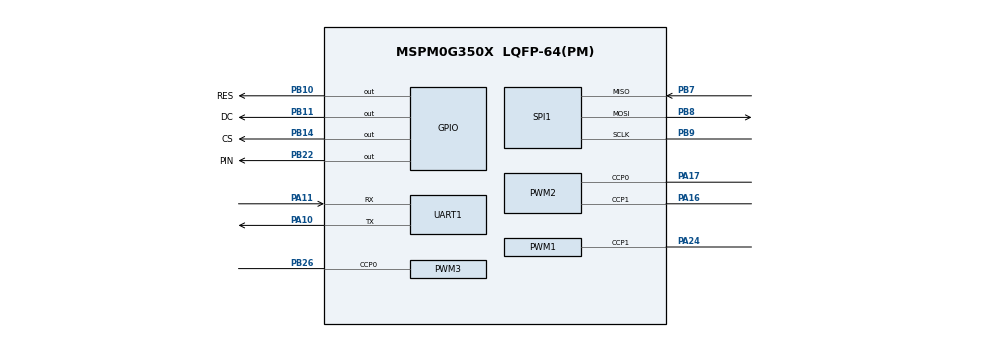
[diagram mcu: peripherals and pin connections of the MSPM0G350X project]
/**
 * @cliArgs --device "MSPM0G350X" --part "Default" --package "LQFP-64(PM)" --product "mspm0_sdk@2.04.00.06"
 * @versions {"tool":"1.22.0+3893"}
 */

/**
 * Import the modules used in this configuration.
 */
const GPIO   = scripting.addModule("/ti/driverlib/GPIO", {}, false);
const GPIO1  = GPIO.addInstance();
const GPIO2  = GPIO.addInstance();
const GPIO3  = GPIO.addInstance();
const GPIO4  = GPIO.addInstance();
const GPIO5  = GPIO.addInstance();
const GPIO6  = GPIO.addInstance();
const GPIO7  = GPIO.addInstance();
const GPIO8  = GPIO.addInstance();
const GPIO9  = GPIO.addInstance();
const PWM    = scripting.addModule("/ti/driverlib/PWM", {}, false);
const PWM1   = PWM.addInstance();
const PWM2   = PWM.addInstance();
const PWM3   = PWM.addInstance();
const SPI    = scripting.addModule("/ti/driverlib/SPI", {}, false);
const SPI1   = SPI.addInstance();
const SYSCTL = scripting.addModule("/ti/driverlib/SYSCTL");
const TIMER  = scripting.addModule("/ti/driverlib/TIMER", {}, false);
const TIMER1 = TIMER.addInstance();
const TIMER2 = TIMER.addInstance();
const UART   = scripting.addModule("/ti/driverlib/UART", {}, false);
const UART1  = UART.addInstance();
const UART2  = UART.addInstance();

/**
 * Write custom configuration values to the imported modules.
 */
const divider9       = system.clockTree["UDIV"];
divider9.divideValue = 2;

const mux4       = system.clockTree["EXHFMUX"];
mux4.inputSelect = "EXHFMUX_XTAL";

const mux8       = system.clockTree["HSCLKMUX"];
mux8.inputSelect = "HSCLKMUX_SYSPLL2X";

const mux12       = system.clockTree["SYSPLLMUX"];
mux12.inputSelect = "zSYSPLLMUX_HFCLK";

const pinFunction4        = system.clockTree["HFXT"];
pinFunction4.inputFreq    = 40;
pinFunction4.enable       = true;
pinFunction4.HFCLKMonitor = true;
pinFunction4.HFXTStartup  = 20;

GPIO1.$name                          = "LED";
GPIO1.associatedPins[0].$name        = "PIN";
GPIO1.associatedPins[0].ioStructure  = "SD";
GPIO1.associatedPins[0].assignedPort = "PORTB";
GPIO1.associatedPins[0].assignedPin  = "22";
GPIO1.associatedPins[0].pin.$assign  = "PB22";

const Board = scripting.addModule("/ti/driverlib/Board", {}, false);

GPIO2.$name                         = "OLED";
GPIO2.port                          = "PORTB";
GPIO2.associatedPins.create(3);
GPIO2.associatedPins[0].$name       = "RES";
GPIO2.associatedPins[0].ioStructure = "SD";
GPIO2.associatedPins[0].assignedPin = "10";
GPIO2.associatedPins[0].pin.$assign = "PB10";
GPIO2.associatedPins[1].$name       = "DC";
GPIO2.associatedPins[1].ioStructure = "SD";
GPIO2.associatedPins[1].assignedPin = "11";
GPIO2.associatedPins[1].pin.$assign = "PB11";
GPIO2.associatedPins[2].$name       = "CS";
GPIO2.associatedPins[2].ioStructure = "SD";
GPIO2.associatedPins[2].assignedPin = "14";
GPIO2.associatedPins[2].pin.$assign = "PB14";

GPIO3.$name                              = "KEY";
GPIO3.associatedPins.create(4);
GPIO3.associatedPins[0].$name            = "KEY1";
GPIO3.associatedPins[0].direction        = "INPUT";
GPIO3.associatedPins[0].assignedPort     = "PORTA";
GPIO3.associatedPins[0].internalResistor = "PULL_UP";
GPIO3.associatedPins[0].assignedPin      = "22";
GPIO3.associatedPins[1].$name            = "KEY2";
GPIO3.associatedPins[1].direction        = "INPUT";
GPIO3.associatedPins[1].internalResistor = "PULL_UP";
GPIO3.associatedPins[1].assignedPort     = "PORTA";
GPIO3.associatedPins[1].assignedPin      = "8";
GPIO3.associatedPins[2].$name            = "KEY3";
GPIO3.associatedPins[2].direction        = "INPUT";
GPIO3.associatedPins[2].internalResistor = "PULL_UP";
GPIO3.associatedPins[2].assignedPort     = "PORTB";
GPIO3.associatedPins[2].assignedPin      = "23";
GPIO3.associatedPins[3].$name            = "KEY4";
GPIO3.associatedPins[3].direction        = "INPUT";
GPIO3.associatedPins[3].internalResistor = "PULL_UP";
GPIO3.associatedPins[3].assignedPort     = "PORTB";
GPIO3.associatedPins[3].assignedPin      = "21";

GPIO4.$name                          = "IIC_Software";
GPIO4.port                           = "PORTA";
GPIO4.associatedPins.create(2);
GPIO4.associatedPins[0].$name        = "SCL";
GPIO4.associatedPins[0].initialValue = "SET";
GPIO4.associatedPins[0].ioStructure  = "OD";
GPIO4.associatedPins[0].assignedPin  = "1";
GPIO4.associatedPins[1].$name        = "SDA";
GPIO4.associatedPins[1].initialValue = "SET";
GPIO4.associatedPins[1].ioStructure  = "OD";
GPIO4.associatedPins[1].assignedPin  = "0";

GPIO5.$name                          = "TB6612";
GPIO5.associatedPins.create(9);
GPIO5.associatedPins[0].initialValue = "SET";
GPIO5.associatedPins[0].$name        = "AIN1";
GPIO5.associatedPins[0].assignedPort = "PORTA";
GPIO5.associatedPins[0].assignedPin  = "12";
GPIO5.associatedPins[1].$name        = "AIN2";
GPIO5.associatedPins[1].initialValue = "SET";
GPIO5.associatedPins[1].assignedPort = "PORTA";
GPIO5.associatedPins[1].assignedPin  = "13";
GPIO5.associatedPins[2].$name        = "BIN1";
GPIO5.associatedPins[2].initialValue = "SET";
GPIO5.associatedPins[2].assignedPort = "PORTA";
GPIO5.associatedPins[2].assignedPin  = "14";
GPIO5.associatedPins[3].$name        = "BIN2";
GPIO5.associatedPins[3].initialValue = "SET";
GPIO5.associatedPins[3].assignedPort = "PORTA";
GPIO5.associatedPins[3].assignedPin  = "15";
GPIO5.associatedPins[4].$name        = "CIN1";
GPIO5.associatedPins[4].initialValue = "SET";
GPIO5.associatedPins[4].assignedPort = "PORTB";
GPIO5.associatedPins[4].assignedPin  = "12";
GPIO5.associatedPins[5].$name        = "CIN2";
GPIO5.associatedPins[5].initialValue = "SET";
GPIO5.associatedPins[5].assignedPort = "PORTB";
GPIO5.associatedPins[5].assignedPin  = "13";
GPIO5.associatedPins[6].$name        = "DIN1";
GPIO5.associatedPins[6].initialValue = "SET";
GPIO5.associatedPins[6].assignedPort = "PORTB";
GPIO5.associatedPins[6].assignedPin  = "19";
GPIO5.associatedPins[7].initialValue = "SET";
GPIO5.associatedPins[7].assignedPort = "PORTB";
GPIO5.associatedPins[7].assignedPin  = "20";
GPIO5.associatedPins[7].$name        = "DIN2";
GPIO5.associatedPins[8].$name        = "STBY";
GPIO5.associatedPins[8].assignedPort = "PORTB";
GPIO5.associatedPins[8].assignedPin  = "24";

GPIO6.$name                               = "ENCODER";
GPIO6.associatedPins.create(8);
GPIO6.associatedPins[0].$name             = "E1A";
GPIO6.associatedPins[0].direction         = "INPUT";
GPIO6.associatedPins[0].assignedPort      = "PORTB";
GPIO6.associatedPins[0].assignedPin       = "18";
GPIO6.associatedPins[0].interruptEn       = true;
GPIO6.associatedPins[0].interruptPriority = "0";
GPIO6.associatedPins[0].polarity          = "RISE";
GPIO6.associatedPins[1].$name             = "E1B";
GPIO6.associatedPins[1].direction         = "INPUT";
GPIO6.associatedPins[1].assignedPort      = "PORTA";
GPIO6.associatedPins[1].assignedPin       = "25";
GPIO6.associatedPins[1].interruptEn       = true;
GPIO6.associatedPins[1].interruptPriority = "0";
GPIO6.associatedPins[1].polarity          = "RISE";
GPIO6.associatedPins[2].$name             = "E2A";
GPIO6.associatedPins[2].direction         = "INPUT";
GPIO6.associatedPins[2].assignedPort      = "PORTA";
GPIO6.associatedPins[2].assignedPin       = "26";
GPIO6.associatedPins[2].interruptEn       = true;
GPIO6.associatedPins[2].interruptPriority = "0";
GPIO6.associatedPins[2].polarity          = "RISE";
GPIO6.associatedPins[3].$name             = "E2B";
GPIO6.associatedPins[3].direction         = "INPUT";
GPIO6.associatedPins[3].assignedPort      = "PORTA";
GPIO6.associatedPins[3].assignedPin       = "27";
GPIO6.associatedPins[3].interruptEn       = true;
GPIO6.associatedPins[3].interruptPriority = "0";
GPIO6.associatedPins[3].polarity          = "RISE";
GPIO6.associatedPins[4].$name             = "E3A";
GPIO6.associatedPins[4].direction         = "INPUT";
GPIO6.associatedPins[4].assignedPort      = "PORTA";
GPIO6.associatedPins[4].assignedPin       = "28";
GPIO6.associatedPins[4].interruptEn       = true;
GPIO6.associatedPins[4].interruptPriority = "0";
GPIO6.associatedPins[4].polarity          = "RISE";
GPIO6.associatedPins[5].$name             = "E3B";
GPIO6.associatedPins[5].direction         = "INPUT";
GPIO6.associatedPins[5].assignedPort      = "PORTA";
GPIO6.associatedPins[5].assignedPin       = "29";
GPIO6.associatedPins[5].interruptEn       = true;
GPIO6.associatedPins[5].interruptPriority = "0";
GPIO6.associatedPins[5].polarity          = "RISE";
GPIO6.associatedPins[6].$name             = "E4A";
GPIO6.associatedPins[6].direction         = "INPUT";
GPIO6.associatedPins[6].assignedPort      = "PORTA";
GPIO6.associatedPins[6].assignedPin       = "30";
GPIO6.associatedPins[6].interruptEn       = true;
GPIO6.associatedPins[6].interruptPriority = "0";
GPIO6.associatedPins[6].polarity          = "RISE";
GPIO6.associatedPins[7].$name             = "E4B";
GPIO6.associatedPins[7].direction         = "INPUT";
GPIO6.associatedPins[7].assignedPort      = "PORTA";
GPIO6.associatedPins[7].assignedPin       = "31";
GPIO6.associatedPins[7].interruptEn       = true;
GPIO6.associatedPins[7].interruptPriority = "0";
GPIO6.associatedPins[7].polarity          = "RISE";

GPIO7.$name                         = "xunji";
GPIO7.port                          = "PORTB";
GPIO7.associatedPins.create(8);
GPIO7.associatedPins[0].$name       = "x1";
GPIO7.associatedPins[0].direction   = "INPUT";
GPIO7.associatedPins[0].assignedPin = "0";
GPIO7.associatedPins[1].$name       = "x2";
GPIO7.associatedPins[1].direction   = "INPUT";
GPIO7.associatedPins[1].assignedPin = "1";
GPIO7.associatedPins[2].$name       = "x3";
GPIO7.associatedPins[2].direction   = "INPUT";
GPIO7.associatedPins[2].assignedPin = "2";
GPIO7.associatedPins[3].$name       = "x4";
GPIO7.associatedPins[3].direction   = "INPUT";
GPIO7.associatedPins[3].assignedPin = "3";
GPIO7.associatedPins[4].$name       = "x5";
GPIO7.associatedPins[4].direction   = "INPUT";
GPIO7.associatedPins[4].assignedPin = "4";
GPIO7.associatedPins[5].$name       = "x6";
GPIO7.associatedPins[5].direction   = "INPUT";
GPIO7.associatedPins[5].assignedPin = "5";
GPIO7.associatedPins[6].$name       = "x7";
GPIO7.associatedPins[6].direction   = "INPUT";
GPIO7.associatedPins[6].assignedPin = "6";
GPIO7.associatedPins[7].$name       = "x8";
GPIO7.associatedPins[7].direction   = "INPUT";
GPIO7.associatedPins[7].assignedPin = "25";

GPIO8.$name                          = "BEEP";
GPIO8.associatedPins[0].$name        = "beep";
GPIO8.associatedPins[0].assignedPort = "PORTA";
GPIO8.associatedPins[0].assignedPin  = "21";
GPIO8.associatedPins[0].initialValue = "SET";

GPIO9.$name                         = "HC05";
GPIO9.port                          = "PORTA";
GPIO9.associatedPins[0].$name       = "STATE";
GPIO9.associatedPins[0].direction   = "INPUT";
GPIO9.associatedPins[0].assignedPin = "7";

PWM1.$name                      = "PWM_0";
PWM1.timerStartTimer            = true;
PWM1.clockDivider               = 8;
PWM1.peripheral.$assign         = "TIMG7";
PWM1.peripheral.ccp1Pin.$assign = "PA24";
PWM1.PWM_CHANNEL_0.$name        = "ti_driverlib_pwm_PWMTimerCC0";
PWM1.PWM_CHANNEL_1.$name        = "ti_driverlib_pwm_PWMTimerCC1";
PWM1.PWM_CHANNEL_1.invert       = true;
PWM1.ccp0PinConfig.$name        = "ti_driverlib_gpio_GPIOPinGeneric5";
PWM1.ccp1PinConfig.$name        = "ti_driverlib_gpio_GPIOPinGeneric6";

PWM2.$name                      = "PWM_1";
PWM2.timerStartTimer            = true;
PWM2.clockDivider               = 8;
PWM2.peripheral.ccp0Pin.$assign = "PA17";
PWM2.peripheral.ccp1Pin.$assign = "PA16";
PWM2.PWM_CHANNEL_0.$name        = "ti_driverlib_pwm_PWMTimerCC2";
PWM2.PWM_CHANNEL_0.invert       = true;
PWM2.PWM_CHANNEL_1.$name        = "ti_driverlib_pwm_PWMTimerCC3";
PWM2.PWM_CHANNEL_1.invert       = true;
PWM2.ccp0PinConfig.$name        = "ti_driverlib_gpio_GPIOPinGeneric7";
PWM2.ccp1PinConfig.$name        = "ti_driverlib_gpio_GPIOPinGeneric8";

PWM3.$name                      = "PWM_2";
PWM3.clockDivider               = 4;
PWM3.timerStartTimer            = true;
PWM3.peripheral.ccp0Pin.$assign = "PB26";
PWM3.PWM_CHANNEL_0.$name        = "ti_driverlib_pwm_PWMTimerCC4";
PWM3.PWM_CHANNEL_0.invert       = true;
PWM3.PWM_CHANNEL_1.$name        = "ti_driverlib_pwm_PWMTimerCC5";
PWM3.ccp0PinConfig.$name        = "ti_driverlib_gpio_GPIOPinGeneric11";
PWM3.ccp1PinConfig.$name        = "ti_driverlib_gpio_GPIOPinGeneric12";

SPI1.frameFormat                        = "MOTO3";
SPI1.$name                              = "SPI_OLED";
SPI1.targetBitRate                      = 20000000;
SPI1.peripheral.$assign                 = "SPI1";
SPI1.peripheral.sclkPin.$assign         = "PB9";
SPI1.peripheral.mosiPin.$assign         = "PB8";
SPI1.peripheral.misoPin.$assign         = "PB7";
SPI1.sclkPinConfig.direction            = scripting.forceWrite("OUTPUT");
SPI1.sclkPinConfig.onlyInternalResistor = scripting.forceWrite(false);
SPI1.sclkPinConfig.passedPeripheralType = scripting.forceWrite("Digital");
SPI1.sclkPinConfig.$name                = "ti_driverlib_gpio_GPIOPinGeneric2";
SPI1.mosiPinConfig.direction            = scripting.forceWrite("OUTPUT");
SPI1.mosiPinConfig.hideOutputInversion  = scripting.forceWrite(false);
SPI1.mosiPinConfig.onlyInternalResistor = scripting.forceWrite(false);
SPI1.mosiPinConfig.passedPeripheralType = scripting.forceWrite("Digital");
SPI1.mosiPinConfig.$name                = "ti_driverlib_gpio_GPIOPinGeneric3";
SPI1.misoPinConfig.onlyInternalResistor = scripting.forceWrite(false);
SPI1.misoPinConfig.passedPeripheralType = scripting.forceWrite("Digital");
SPI1.misoPinConfig.$name                = "ti_driverlib_gpio_GPIOPinGeneric4";

SYSCTL.forceDefaultClkConfig = true;
SYSCTL.validateClkStatus     = true;
SYSCTL.clockTreeEn           = true;

TIMER1.$name             = "TIMER_0";
TIMER1.timerMode         = "PERIODIC";
TIMER1.timerStartTimer   = true;
TIMER1.interrupts        = ["ZERO"];
TIMER1.timerClkDiv       = 8;
TIMER1.interruptPriority = "0";
TIMER1.timerPeriod       = "5 ms";

TIMER2.$name              = "TIMER_1";
TIMER2.timerStartTimer    = true;
TIMER2.timerClkDiv        = 8;
TIMER2.timerClkPrescale   = 100;
TIMER2.timerMode          = "PERIODIC";
TIMER2.timerPeriod        = "100 ms";
TIMER2.interrupts         = ["ZERO"];
TIMER2.peripheral.$assign = "TIMA0";

UART1.$name                        = "UART_0";
UART1.targetBaudRate               = 115200;
UART1.peripheral.$assign           = "UART0";
UART1.peripheral.rxPin.$assign     = "PA11";
UART1.peripheral.txPin.$assign     = "PA10";
UART1.txPinConfig.$name            = "ti_driverlib_gpio_GPIOPinGeneric0";
UART1.txPinConfig.enableConfig     = true;
UART1.txPinConfig.internalResistor = "PULL_UP";
UART1.rxPinConfig.$name            = "ti_driverlib_gpio_GPIOPinGeneric1";
UART1.rxPinConfig.enableConfig     = true;
UART1.rxPinConfig.internalResistor = "PULL_UP";

UART2.$name                            = "UART_2";
UART2.uartClkDiv                       = "4";
UART2.enabledInterrupts                = ["RX"];
UART2.peripheral.$assign               = "UART2";
UART2.txPinConfig.direction            = scripting.forceWrite("OUTPUT");
UART2.txPinConfig.hideOutputInversion  = scripting.forceWrite(false);
UART2.txPinConfig.onlyInternalResistor = scripting.forceWrite(false);
UART2.txPinConfig.passedPeripheralType = scripting.forceWrite("Digital");
UART2.txPinConfig.$name                = "ti_driverlib_gpio_GPIOPinGeneric9";
UART2.rxPinConfig.hideOutputInversion  = scripting.forceWrite(false);
UART2.rxPinConfig.onlyInternalResistor = scripting.forceWrite(false);
UART2.rxPinConfig.passedPeripheralType = scripting.forceWrite("Digital");
UART2.rxPinConfig.$name                = "ti_driverlib_gpio_GPIOPinGeneric10";

/**
 * Pinmux solution for unlocked pins/peripherals. This ensures that minor changes to the automatic solver in a future
 * version of the tool will not impact the pinmux you originally saw.  These lines can be completely deleted in order to
 * re-solve from scratch.
 */
pinFunction4.peripheral.$suggestSolution           = "SYSCTL";
pinFunction4.peripheral.hfxInPin.$suggestSolution  = "PA5";
pinFunction4.peripheral.hfxOutPin.$suggestSolution = "PA6";
Board.peripheral.$suggestSolution                  = "DEBUGSS";
Board.peripheral.swclkPin.$suggestSolution         = "PA20";
Board.peripheral.swdioPin.$suggestSolution         = "PA19";
GPIO3.associatedPins[0].pin.$suggestSolution       = "PA22";
GPIO3.associatedPins[1].pin.$suggestSolution       = "PA8";
GPIO3.associatedPins[2].pin.$suggestSolution       = "PB23";
GPIO3.associatedPins[3].pin.$suggestSolution       = "PB21";
GPIO4.associatedPins[0].pin.$suggestSolution       = "PA1";
GPIO4.associatedPins[1].pin.$suggestSolution       = "PA0";
GPIO5.associatedPins[0].pin.$suggestSolution       = "PA12";
GPIO5.associatedPins[1].pin.$suggestSolution       = "PA13";
GPIO5.associatedPins[2].pin.$suggestSolution       = "PA14";
GPIO5.associatedPins[3].pin.$suggestSolution       = "PA15";
GPIO5.associatedPins[4].pin.$suggestSolution       = "PB12";
GPIO5.associatedPins[5].pin.$suggestSolution       = "PB13";
GPIO5.associatedPins[6].pin.$suggestSolution       = "PB19";
GPIO5.associatedPins[7].pin.$suggestSolution       = "PB20";
GPIO5.associatedPins[8].pin.$suggestSolution       = "PB24";
GPIO6.associatedPins[0].pin.$suggestSolution       = "PB18";
GPIO6.associatedPins[1].pin.$suggestSolution       = "PA25";
GPIO6.associatedPins[2].pin.$suggestSolution       = "PA26";
GPIO6.associatedPins[3].pin.$suggestSolution       = "PA27";
GPIO6.associatedPins[4].pin.$suggestSolution       = "PA28";
GPIO6.associatedPins[5].pin.$suggestSolution       = "PA29";
GPIO6.associatedPins[6].pin.$suggestSolution       = "PA30";
GPIO6.associatedPins[7].pin.$suggestSolution       = "PA31";
GPIO7.associatedPins[0].pin.$suggestSolution       = "PB0";
GPIO7.associatedPins[1].pin.$suggestSolution       = "PB1";
GPIO7.associatedPins[2].pin.$suggestSolution       = "PB2";
GPIO7.associatedPins[3].pin.$suggestSolution       = "PB3";
GPIO7.associatedPins[4].pin.$suggestSolution       = "PB4";
GPIO7.associatedPins[5].pin.$suggestSolution       = "PB5";
GPIO7.associatedPins[6].pin.$suggestSolution       = "PB6";
GPIO7.associatedPins[7].pin.$suggestSolution       = "PB25";
GPIO8.associatedPins[0].pin.$suggestSolution       = "PA21";
GPIO9.associatedPins[0].pin.$suggestSolution       = "PA7";
PWM1.peripheral.ccp0Pin.$suggestSolution           = "PA3";
PWM2.peripheral.$suggestSolution                   = "TIMA1";
PWM3.peripheral.$suggestSolution                   = "TIMG6";
PWM3.peripheral.ccp1Pin.$suggestSolution           = "PB27";
TIMER1.peripheral.$suggestSolution                 = "TIMG0";
UART2.peripheral.rxPin.$suggestSolution            = "PB16";
UART2.peripheral.txPin.$suggestSolution            = "PA23";
